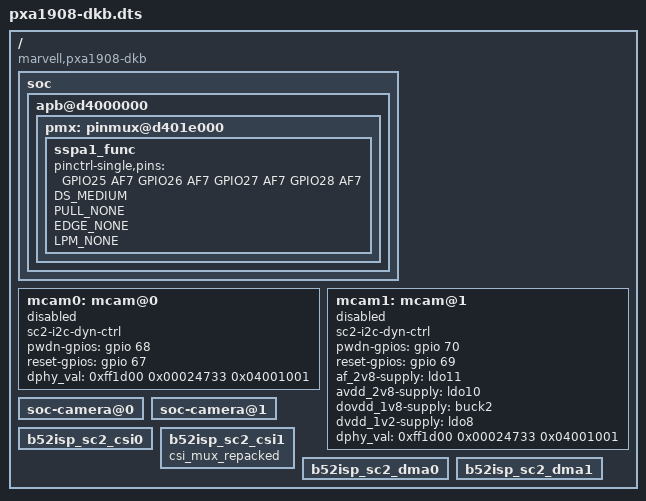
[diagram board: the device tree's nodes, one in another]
/*
 *  Copyright (C) 2014 Marvell Technology Group Ltd.
 *  Author: Qiming Wu <wuqm@marvell.com>
 *
 *  This program is free software; you can redistribute it and/or modify
 *  it under the terms of the GNU General Public License version 2 as
 *  publishhed by the Free Software Foundation.
 */

/dts-v1/;
#include "pxa1908-dkb.dtsi"

/ {
	compatible = "marvell,pxa1908-dkb", "marvell,pxa1908";

	soc {
		apb@d4000000 {
			pmx: pinmux@d401e000 {
				sspa1_func: sspa1_func {
					pinctrl-single,pins = <
						GPIO25 AF7
						GPIO26 AF7
						GPIO27 AF7
						GPIO28 AF7
					>;
					DS_MEDIUM;PULL_NONE;EDGE_NONE;LPM_NONE;
				};
			};
		};
	};

	mcam0:mcam@0 {
		sc2-i2c-dyn-ctrl;
		pwdn-gpios = <&gpio 68 0>;
		reset-gpios = <&gpio 67 0>;
		/*
		af_2v8-supply = <&ldo10>;
		avdd_2v8-supply = <&ldo11>;
		dovdd_1v8-supply = <&voutsw>;
		dvdd_1v2-supply = <&ldo12>;
		*/
		dphy_val = <0xff1d00 0x00024733 0x04001001>;
		status = "disable";
	};

	mcam1:mcam@1 {
		sc2-i2c-dyn-ctrl;
		pwdn-gpios = <&gpio 70 0>;
		reset-gpios = <&gpio 69 0>;

		af_2v8-supply = <&ldo11>;
		avdd_2v8-supply = <&ldo10>;
		dovdd_1v8-supply = <&buck2>;
		dvdd_1v2-supply = <&ldo8>;

		dphy_val = <0xff1d00 0x00024733 0x04001001>;
		status = "disable";
	};

	soc-camera@0 {
		status = "okay";
	};

	soc-camera@1 {
		status = "okay";
	};

	b52isp_sc2_csi0 {
	        status = "okay";
	};

	b52isp_sc2_csi1 {
			csi_mux_repacked;
	        status = "okay";
	};

	b52isp_sc2_dma0 {
	        status = "okay";
	};

	b52isp_sc2_dma1 {
	        status = "okay";
	};
};
